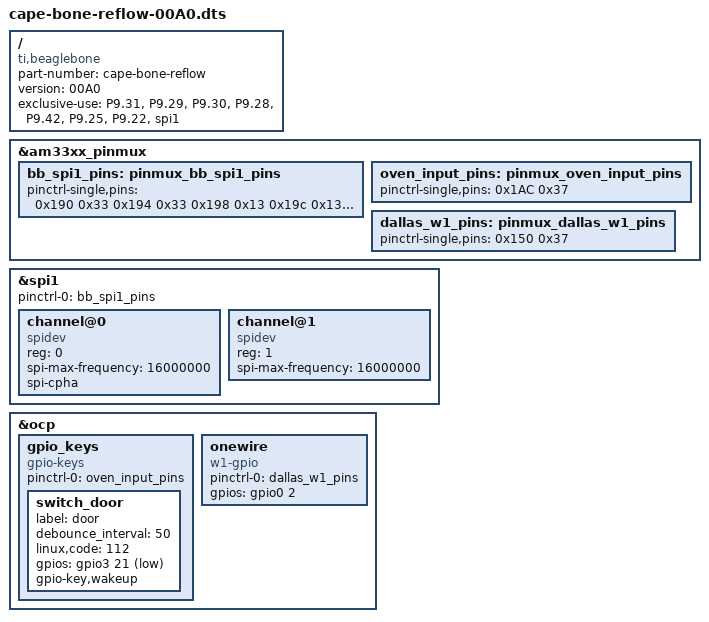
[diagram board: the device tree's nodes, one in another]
/*
 * Copyright (C) 2013 CircuitCo
 *
 * Virtual cape for SPI1 on connector pins P9.29 P9.31 P9.30 P9.28
 *
 * This program is free software; you can redistribute it and/or modify
 * it under the terms of the GNU General Public License version 2 as
 * published by the Free Software Foundation.
 */
/dts-v1/;
/plugin/;

/ {
	compatible = "ti,beaglebone", "ti,beaglebone-black", "ti,beaglebone-green";

	/* identification */
	part-number = "cape-bone-reflow";
	version = "00A0";

	/* state the resources this cape uses */
	exclusive-use =
		/* the pin header uses */
		"P9.31",	/* spi1_sclk */
		"P9.29",	/* spi1_d0 */
		"P9.30",	/* spi1_d1 */
		"P9.28",	/* spi1_cs0 */
		"P9.42",	/* spi1_cs1 */
		"P9.25", /* OVEN DOOR	*/
		"P9.22", /* Dallas 1W   */
		/* the hardware ip uses */
		"spi1";

	fragment@0 {
		target = <&am33xx_pinmux>;
		__overlay__ {
			/* default state has all gpios released and mode set to uart1 */
			bb_spi1_pins: pinmux_bb_spi1_pins {
				pinctrl-single,pins = <
					0x190 0x33	/* mcasp0_aclkx.spi1_sclk, INPUT_PULLUP | MODE3 */
					0x194 0x33	/* mcasp0_fsx.spi1_d0, INPUT_PULLUP | MODE3 */
					0x198 0x13	/* mcasp0_axr0.spi1_d1, OUTPUT_PULLUP | MODE3 */
					0x19c 0x13	/* mcasp0_ahclkr.spi1_cs0, OUTPUT_PULLUP | MODE3 */
					0x164 0x12	/* eCAP0_in_PWM0_out.spi1_cs1 OUTPUT_PULLUP | MODE2 */
				>;
			};
			oven_input_pins: pinmux_oven_input_pins{
				pinctrl-single,pins = <
					0x1AC 0x37 // P9_25 = Door open  = GPIO3_21
				>;
			};
			dallas_w1_pins: pinmux_dallas_w1_pins {
				pinctrl-single,pins = <
					0x150 0x37	// Dallas 1W
				>;
			};
		};
	};

	fragment@1 {
		target = <&spi1>;	/* spi1 is numbered correctly */
		__overlay__ {
			status = "okay";
			pinctrl-names = "default";
			pinctrl-0 = <&bb_spi1_pins>;

			#address-cells = <1>;
			#size-cells = <0>;

			channel@0 {
				#address-cells = <1>;
				#size-cells = <0>;

				compatible = "spidev";

				reg = <0>;
				spi-max-frequency = <16000000>;
				spi-cpha;
			};

			channel@1 {
				#address-cells = <1>;
				#size-cells = <0>;

				compatible = "spidev";

				reg = <1>;
				spi-max-frequency = <16000000>;
			};
		};
	};

	fragment@3 {
		target = <&ocp>;
		__overlay__ {
			#address-cells = <1>;
			#size-cells = <1>;

			gpio_keys {
				compatible = "gpio-keys";
				pinctrl-names = "default";
				pinctrl-0 = <&oven_input_pins>;
				#address-cells = <1>;
				#size-cells = <0>;

				switch_door {
					label               = "door";
					debounce_interval   = <50>;
					linux,code          = <112>;
					gpios               = <&gpio3 21 0x5>;
					gpio-key,wakeup;
				};
			};

			onewire {
				compatible      = "w1-gpio";
				pinctrl-names   = "default";
				pinctrl-0       = <&dallas_w1_pins>;
				status          = "okay";
				gpios           = <&gpio0 2 0>;
			};
		};
	};
};
